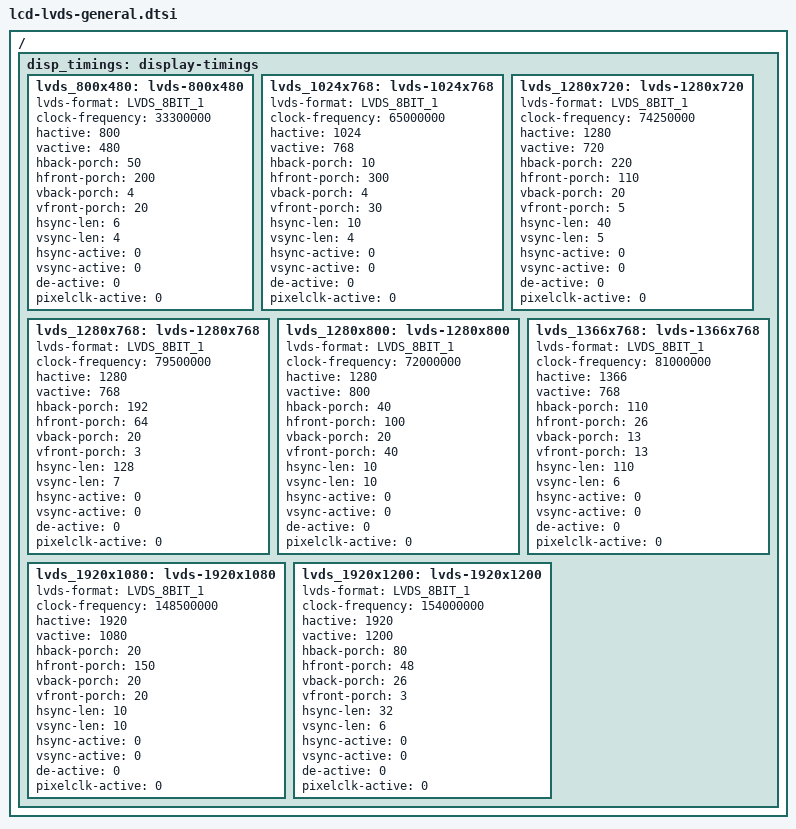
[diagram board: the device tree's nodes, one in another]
/*
 * Advantech. edp general LCD
 *
 */
/ {
	disp_timings: display-timings {
		lvds_800x480: lvds-800x480 {
			lvds-format = <LVDS_8BIT_1>;
			clock-frequency = <33300000>;
			hactive = <800>;
			vactive = <480>;
			hback-porch = <50>;
			hfront-porch = <200>;
			vback-porch = <4>;
			vfront-porch = <20>;
			hsync-len = <6>;
			vsync-len = <4>;
			hsync-active = <0>;
			vsync-active = <0>;
			de-active = <0>;
			pixelclk-active = <0>;
		};

		lvds_1024x768: lvds-1024x768 {
			lvds-format = <LVDS_8BIT_1>;
			clock-frequency = <65000000>;
			hactive = <1024>;
			vactive = <768>;
			hback-porch = <10>;
			hfront-porch = <300>;
			vback-porch = <4>;
			vfront-porch = <30>;
			hsync-len = <10>;
			vsync-len = <4>;
			hsync-active = <0>;
			vsync-active = <0>;
			de-active = <0>;
			pixelclk-active = <0>;
		};

		lvds_1280x720: lvds-1280x720 {
			lvds-format = <LVDS_8BIT_1>;
			clock-frequency = <74250000>;
			hactive = <1280>;
			vactive = <720>;
			hback-porch = <220>;
			hfront-porch = <110>;
			vback-porch = <20>;
			vfront-porch = <5>;
			hsync-len = <40>;
			vsync-len = <5>;
			hsync-active = <0>;
			vsync-active = <0>;
			de-active = <0>;
			pixelclk-active = <0>;
		};

		lvds_1280x768: lvds-1280x768 {
			lvds-format = <LVDS_8BIT_1>;
			clock-frequency = <79500000>;
			hactive = <1280>;
			vactive = <768>;
			hback-porch = <192>;
			hfront-porch = <64>;
			vback-porch = <20>;
			vfront-porch = <3>;
			hsync-len = <128>;
			vsync-len = <7>;
			hsync-active = <0>;
			vsync-active = <0>;
			de-active = <0>;
			pixelclk-active = <0>;
		};

		lvds_1280x800: lvds-1280x800 {
			lvds-format = <LVDS_8BIT_1>;
			clock-frequency = <72000000>;
			hactive = <1280>;
			vactive = <800>;
			hback-porch = <40>;
			hfront-porch = <100>;
			vback-porch = <20>;
			vfront-porch = <40>;
			hsync-len = <10>;
			vsync-len = <10>;
			hsync-active = <0>;
			vsync-active = <0>;
			de-active = <0>;
			pixelclk-active = <0>;
		};

		lvds_1366x768: lvds-1366x768 {
			lvds-format = <LVDS_8BIT_1>;
			clock-frequency = <81000000>;
			hactive = <1366>;
			vactive = <768>;
			hback-porch = <110>;
			hfront-porch = <26>;
			vback-porch = <13>;
			vfront-porch = <13>;
			hsync-len = <110>;
			vsync-len = <6>;
			hsync-active = <0>;
			vsync-active = <0>;
			de-active = <0>;
			pixelclk-active = <0>;
		};

		lvds_1920x1080: lvds-1920x1080 {
			lvds-format = <LVDS_8BIT_1>;
			clock-frequency = <148500000>;
			hactive = <1920>;
			vactive = <1080>;
			hback-porch = <20>;
			hfront-porch = <150>;
			vback-porch = <20>;
			vfront-porch = <20>;
			hsync-len = <10>;
			vsync-len = <10>;
			hsync-active = <0>;
			vsync-active = <0>;
			de-active = <0>;
			pixelclk-active = <0>;
		};

		lvds_1920x1200: lvds-1920x1200 {
			lvds-format = <LVDS_8BIT_1>;
			clock-frequency = <154000000>;
			hactive = <1920>;
			vactive = <1200>;
			hback-porch = <80>;
			hfront-porch = <48>;
			vback-porch = <26>;
			vfront-porch = <3>;
			hsync-len = <32>;
			vsync-len = <6>;
			hsync-active = <0>;
			vsync-active = <0>;
			de-active = <0>;
			pixelclk-active = <0>;
	    };

	};
};
